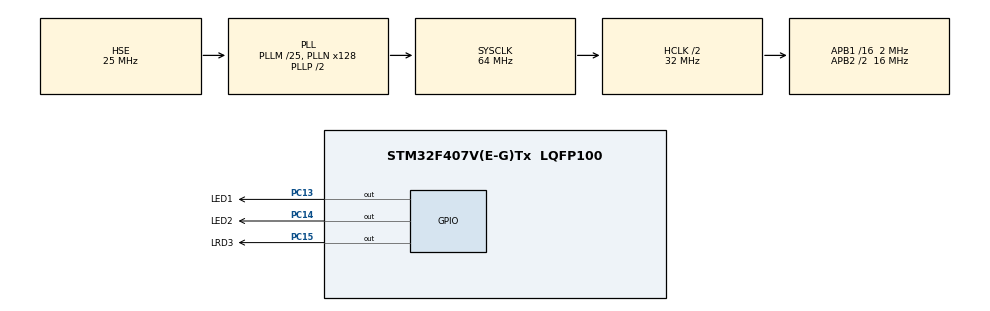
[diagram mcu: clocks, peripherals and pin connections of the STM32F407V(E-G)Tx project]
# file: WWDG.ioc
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Mcu.Family=STM32F4
Mcu.Name=STM32F407V(E-G)Tx
Mcu.Package=LQFP100
NVIC.PriorityGroup=NVIC_PRIORITYGROUP_4
NVIC.WWDG_IRQn=true\:0\:0\:false\:false\:true\:true\:true
PA13.Mode=Serial_Wire
PA13.Signal=SYS_JTMS-SWDIO
PA14.Mode=Serial_Wire
PA14.Signal=SYS_JTCK-SWCLK
PC13-ANTI_TAMP.GPIO_Label=LED1
PC13-ANTI_TAMP.Signal=GPIO_Output
PC14-OSC32_IN.GPIO_Label=LED2
PC14-OSC32_IN.Signal=GPIO_Output
PC15-OSC32_OUT.GPIO_Label=LRD3
PC15-OSC32_OUT.Signal=GPIO_Output
PH0-OSC_IN.Mode=HSE-External-Oscillator
PH0-OSC_IN.Signal=RCC_OSC_IN
PH1-OSC_OUT.Mode=HSE-External-Oscillator
PH1-OSC_OUT.Signal=RCC_OSC_OUT
ProjectManager.HeapSize=0x200
ProjectManager.StackSize=0x400
ProjectManager.TargetToolchain=MDK-ARM V5.27
RCC.48MHZClocksFreq_Value=32000000
RCC.AHBCLKDivider=RCC_SYSCLK_DIV2
RCC.AHBFreq_Value=32000000
RCC.APB1CLKDivider=RCC_HCLK_DIV16
RCC.APB1Freq_Value=2000000
RCC.APB1TimFreq_Value=4000000
RCC.APB2CLKDivider=RCC_HCLK_DIV2
RCC.APB2Freq_Value=16000000
RCC.APB2TimFreq_Value=32000000
RCC.CortexFreq_Value=32000000
RCC.HCLKFreq_Value=32000000
RCC.HSE_VALUE=25000000
RCC.HSI_VALUE=16000000
RCC.LSE_VALUE=32768
RCC.PLLM=25
RCC.PLLN=128
RCC.PLLSourceVirtual=RCC_PLLSOURCE_HSE
RCC.SYSCLKFreq_VALUE=64000000
RCC.SYSCLKSource=RCC_SYSCLKSOURCE_PLLCLK
RCC.VCOOutputFreq_Value=128000000
VP_WWDG_VS_WWDG.Mode=WWDG_Activate
WWDG.Counter=127
WWDG.Prescaler=WWDG_PRESCALER_8
WWDG.Window=100
board=custom

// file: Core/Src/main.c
/* USER CODE BEGIN Header */
/**
  ******************************************************************************
  * @file           : main.c
  * @brief          : Main program body
  ******************************************************************************
  * @attention
  *
  * <h2><center>&copy; Copyright (c) 2024 STMicroelectronics.
  * All rights reserved.</center></h2>
  *
  * This software component is licensed by ST under BSD 3-Clause license,
  * the "License"; You may not use this file except in compliance with the
  * License. You may obtain a copy of the License at:
  *                        opensource.org/licenses/BSD-3-Clause
  *
  ******************************************************************************
  */
/* USER CODE END Header */
#include "main.h"
#include "wwdg.h"
#include "gpio.h"

/* USER CODE BEGIN PV */

// path jlink driver: C:\Keil_v5\ARM\Segger\USBDriver
// 4096 / 4000000 * 64 * 8 =~ 524 ms
// 4096 / 4000000 * 27 * 8 =~ 221 ms
/* USER CODE END PV */

void SystemClock_Config(void);

int main(void)
{

  /* MCU Configuration--------------------------------------------------------*/

  /* Reset of all peripherals, Initializes the Flash interface and the Systick. */
  HAL_Init();

  /* Configure the system clock */
  SystemClock_Config();

//HAL_Delay(1500);
  /* Initialize all configured peripherals */
  MX_GPIO_Init();
  MX_WWDG_Init();

  /* Infinite loop */
  /* USER CODE BEGIN WHILE */
  while (1)
  {
		HAL_Delay(500);
		HAL_WWDG_Refresh(&hwwdg);
		HAL_GPIO_TogglePin(LED1_GPIO_Port, LED1_Pin);

    /* USER CODE END WHILE */

  }
}

void SystemClock_Config(void)
{
  RCC_OscInitTypeDef RCC_OscInitStruct = {0};
  RCC_ClkInitTypeDef RCC_ClkInitStruct = {0};

  /** Configure the main internal regulator output voltage
  */
  __HAL_RCC_PWR_CLK_ENABLE();
  __HAL_PWR_VOLTAGESCALING_CONFIG(PWR_REGULATOR_VOLTAGE_SCALE1);
  /** Initializes the RCC Oscillators according to the specified parameters
  * in the RCC_OscInitTypeDef structure.
  */
  RCC_OscInitStruct.OscillatorType = RCC_OSCILLATORTYPE_HSE;
  RCC_OscInitStruct.HSEState = RCC_HSE_ON;
  RCC_OscInitStruct.PLL.PLLState = RCC_PLL_ON;
  RCC_OscInitStruct.PLL.PLLSource = RCC_PLLSOURCE_HSE;
  RCC_OscInitStruct.PLL.PLLM = 25;
  RCC_OscInitStruct.PLL.PLLN = 128;
  RCC_OscInitStruct.PLL.PLLP = RCC_PLLP_DIV2;
  RCC_OscInitStruct.PLL.PLLQ = 4;
  if (HAL_RCC_OscConfig(&RCC_OscInitStruct) != HAL_OK)
  {
    Error_Handler();
  }
  /** Initializes the CPU, AHB and APB buses clocks
  */
  RCC_ClkInitStruct.ClockType = RCC_CLOCKTYPE_HCLK|RCC_CLOCKTYPE_SYSCLK
                              |RCC_CLOCKTYPE_PCLK1|RCC_CLOCKTYPE_PCLK2;
  RCC_ClkInitStruct.SYSCLKSource = RCC_SYSCLKSOURCE_PLLCLK;
  RCC_ClkInitStruct.AHBCLKDivider = RCC_SYSCLK_DIV2;
  RCC_ClkInitStruct.APB1CLKDivider = RCC_HCLK_DIV16;
  RCC_ClkInitStruct.APB2CLKDivider = RCC_HCLK_DIV2;

  if (HAL_RCC_ClockConfig(&RCC_ClkInitStruct, FLASH_LATENCY_1) != HAL_OK)
  {
    Error_Handler();
  }
}

void Error_Handler(void)
{
  __disable_irq();
  while (1)
  {
  }
}

/************************ (C) COPYRIGHT STMicroelectronics *****END OF FILE****/
